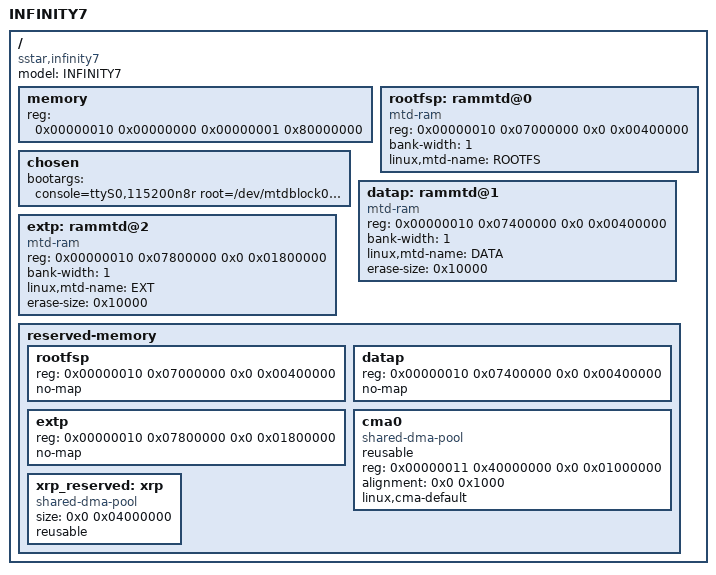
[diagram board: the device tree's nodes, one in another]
/*
* infinity7_aarch64_fpga.dts- Sigmastar
*
* Copyright (c) [2019~2020] SigmaStar Technology.
*
*
* This software is licensed under the terms of the GNU General Public
* License version 2, as published by the Free Software Foundation, and
* may be copied, distributed, and modified under those terms.
*
* This program is distributed in the hope that it will be useful,
* but WITHOUT ANY WARRANTY; without even the implied warranty of
* MERCHANTABILITY or FITNESS FOR A PARTICULAR PURPOSE.  See the
* GNU General Public License version 2 for more details.
*
*/


/dts-v1/;
/memreserve/ 0x1000040000 0x00040000;
#include "infinity7_aarch64_fpga.dtsi"

/ {
    model = "INFINITY7";
    compatible = "sstar,infinity7";
    #address-cells = <2>;
    #size-cells = <2>;

    memory {
        device_type = "memory";
        #address-cells = <2>;
        #size-cells = <2>;
        reg = <0x00000010 0x00000000 0x00000001 0x80000000>;
    };

    chosen {
        bootargs = "console=ttyS0,115200n8r root=/dev/mtdblock0 init=/linuxrc LX_MEM=0x1000000000,0x180000000 mma_heap=mma_heap_name0,miu=0,sz=0x6000000,max_start_off=0x1100000000,max_end_off=0x1106000000, nohz=off";
    };

    rootfsp:rammtd@0 {
        compatible = "mtd-ram";
        reg= <0x00000010 0x07000000 0x0 0x00400000>;
        bank-width = <1>;
        linux,mtd-name = "ROOTFS";
    };

    /* Size of this partition must be identical to the size of data.jffs2 due to JFFS2 limitation */
    datap:rammtd@1 {
        compatible = "mtd-ram";
        reg= <0x00000010 0x07400000 0x0 0x00400000>;
        bank-width = <1>;
        linux,mtd-name = "DATA";
        erase-size = <0x10000>;
    };
    extp:rammtd@2 {
        compatible = "mtd-ram";
        reg= <0x00000010 0x07800000 0x0 0x01800000>;
        bank-width = <1>;
        linux,mtd-name = "EXT";
        erase-size = <0x10000>;
    };

    /*!!IMPORTANT!! The reserved memory must be 1MB aligned*/
    reserved-memory {
        #address-cells = <2>;
        #size-cells = <2>;
        ranges;

        rootfsp {
            reg= <0x00000010 0x07000000 0x0 0x00400000>;
            no-map;
        };

        datap {
            reg= <0x00000010 0x07400000 0x0 0x00400000>;
            no-map;
        };
        extp {
            reg= <0x00000010 0x07800000 0x0 0x01800000>;
            no-map;
        };

        cma0 {
            compatible = "shared-dma-pool";
            reusable;
            reg = <0x00000011 0x40000000 0x0 0x01000000>;
            alignment = <0x0 0x1000>;
            linux,cma-default;
        };
        xrp_reserved: xrp {
            compatible = "shared-dma-pool";
            size = <0x0 0x04000000>;
            reusable;
        };
    };
 
};
